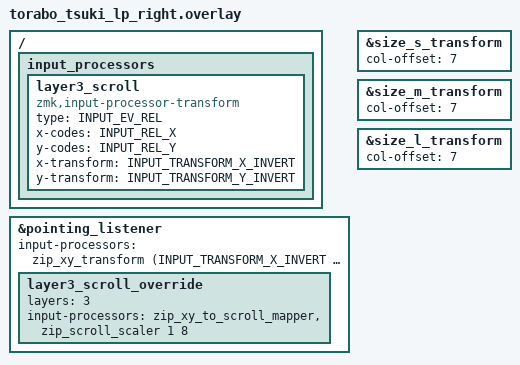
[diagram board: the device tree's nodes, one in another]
#include "torabo_tsuki_lp.dtsi"
#include <input/processors.dtsi>
#include <dt-bindings/zmk/input_transform.h>
#include <dt-bindings/zmk/pointing.h>

/ {
    input_processors {
        layer3_scroll: layer3_scroll {
            compatible = "zmk,input-processor-transform";
            #input-processor-cells = <1>;
            type = <INPUT_EV_REL>;
            x-codes = <INPUT_REL_X>;
            y-codes = <INPUT_REL_Y>;
            x-transform = <INPUT_TRANSFORM_X_INVERT>;
            y-transform = <INPUT_TRANSFORM_Y_INVERT>;
        };
    };
};

&pointing_listener {
    input-processors = <&zip_xy_transform (INPUT_TRANSFORM_X_INVERT | INPUT_TRANSFORM_Y_INVERT)>;

    layer3_scroll_override: layer3_scroll_override {
        layers = <3>;
        input-processors = <&zip_xy_to_scroll_mapper &zip_scroll_scaler 1 8>;
    };
};

&size_s_transform {
    col-offset = <7>;
};

&size_m_transform {
    col-offset = <7>;
};

&size_l_transform {
    col-offset = <7>;
};
